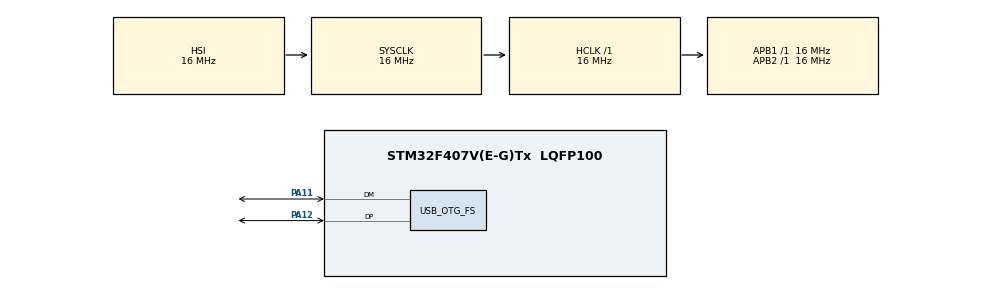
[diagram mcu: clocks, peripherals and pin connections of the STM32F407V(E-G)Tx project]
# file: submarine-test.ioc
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Mcu.Family=STM32F4
Mcu.Name=STM32F407V(E-G)Tx
Mcu.Package=LQFP100
NVIC.OTG_FS_IRQn=true\:0\:0\:false\:false\:true\:false\:true\:true
NVIC.PriorityGroup=NVIC_PRIORITYGROUP_4
PA11.Mode=Device_Only
PA11.Signal=USB_OTG_FS_DM
PA12.Mode=Device_Only
PA12.Signal=USB_OTG_FS_DP
PA13.Mode=Trace_Asynchronous_SW
PA13.Signal=SYS_JTMS-SWDIO
PA14.Mode=Trace_Asynchronous_SW
PA14.Signal=SYS_JTCK-SWCLK
PB3.Mode=Trace_Asynchronous_SW
PB3.Signal=SYS_JTDO-SWO
PH0-OSC_IN.Mode=HSE-External-Oscillator
PH0-OSC_IN.Signal=RCC_OSC_IN
PH1-OSC_OUT.Mode=HSE-External-Oscillator
PH1-OSC_OUT.Signal=RCC_OSC_OUT
ProjectManager.HeapSize=0x200
ProjectManager.StackSize=0x400
ProjectManager.TargetToolchain=STM32CubeIDE
RCC.48MHZClocksFreq_Value=48000000
RCC.AHBFreq_Value=16000000
RCC.APB1Freq_Value=16000000
RCC.APB2Freq_Value=16000000
RCC.CortexFreq_Value=16000000
RCC.HSE_VALUE=25000000
RCC.HSI_VALUE=16000000
RCC.LSE_VALUE=32768
RCC.PLLM=15
RCC.PLLN=144
RCC.PLLQ=5
RCC.SYSCLKFreq_VALUE=16000000
RCC.VCOOutputFreq_Value=240000000
USB_DEVICE.CLASS_NAME_FS=CDC
USB_DEVICE.VirtualMode-CDC_FS=Cdc
USB_DEVICE.VirtualModeFS=Cdc_FS
USB_OTG_FS.VirtualMode=Device_Only
VP_USB_DEVICE_VS_USB_DEVICE_CDC_FS.Mode=CDC_FS
board=custom

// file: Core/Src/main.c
/* USER CODE BEGIN Header */
/**
  ******************************************************************************
  * @file           : main.c
  * @brief          : Main program body
  ******************************************************************************
  * @attention
  *
  * Copyright (c) 2025 STMicroelectronics.
  * All rights reserved.
  *
  * This software is licensed under terms that can be found in the LICENSE file
  * in the root directory of this software component.
  * If no LICENSE file comes with this software, it is provided AS-IS.
  *
  ******************************************************************************
  */
/* USER CODE END Header */
#include "main.h"
#include "usb_device.h"

/* USER CODE BEGIN Includes */
#include <stdio.h>
#include <string.h>
#include "usbd_cdc_if.h"
/* USER CODE END Includes */

void SystemClock_Config(void);
static void MX_GPIO_Init(void);

/* USER CODE BEGIN 0 */

// Redirect printf to USB CDC
int _write(int file, char *ptr, int len)
{
    CDC_Transmit_FS((uint8_t*)ptr, len);
    return len;
}

/* USER CODE END 0 */

int main(void)
{

  /* MCU Configuration--------------------------------------------------------*/

  /* Reset of all peripherals, Initializes the Flash interface and the Systick. */
  HAL_Init();

  /* Configure the system clock */
  SystemClock_Config();

  /* Initialize all configured peripherals */
  MX_GPIO_Init();
  MX_USB_DEVICE_Init();
  /* USER CODE BEGIN 2 */

  // Wait a bit for USB CDC to be ready
  HAL_Delay(1000);

  printf("Hello World!\r\n");
  printf("STM32F407 USB CDC Printf Test\r\n");
  printf("System Clock: %lu Hz\r\n", HAL_RCC_GetSysClockFreq());

  /* USER CODE END 2 */

  /* Infinite loop */
  /* USER CODE BEGIN WHILE */
  uint32_t counter = 0;
  while (1)
  {
    /* USER CODE END WHILE */

    /* USER CODE BEGIN 3 */

    // Turn off both PB0 and PB1 pins completely
    HAL_GPIO_WritePin(GPIOB, GPIO_PIN_0, GPIO_PIN_RESET); // Force PB0 OFF
    HAL_GPIO_WritePin(GPIOB, GPIO_PIN_1, GPIO_PIN_RESET); // PB1 OFF

    // Test only PB1 pin
    printf("Counter: %lu - PB1 turning ON\r\n", counter++);
    HAL_GPIO_WritePin(GPIOB, GPIO_PIN_1, GPIO_PIN_SET);   // Turn on PB1
    HAL_Delay(1000);

    printf("Counter: %lu - PB1 turning OFF\r\n", counter++);
    HAL_GPIO_WritePin(GPIOB, GPIO_PIN_1, GPIO_PIN_RESET); // Turn off PB1
    HAL_Delay(1000);

    printf("Counter: %lu - All pins OFF for 1 second\r\n", counter++);
    HAL_Delay(1000);

  }
  /* USER CODE END 3 */
}

void SystemClock_Config(void)
{
  RCC_OscInitTypeDef RCC_OscInitStruct = {0};
  RCC_ClkInitTypeDef RCC_ClkInitStruct = {0};

  /** Configure the main internal regulator output voltage
  */
  __HAL_RCC_PWR_CLK_ENABLE();
  __HAL_PWR_VOLTAGESCALING_CONFIG(PWR_REGULATOR_VOLTAGE_SCALE1);

  /** Initializes the RCC Oscillators according to the specified parameters
  * in the RCC_OscInitTypeDef structure.
  */
  RCC_OscInitStruct.OscillatorType = RCC_OSCILLATORTYPE_HSI|RCC_OSCILLATORTYPE_HSE;
  RCC_OscInitStruct.HSEState = RCC_HSE_ON;
  RCC_OscInitStruct.HSIState = RCC_HSI_ON;
  RCC_OscInitStruct.HSICalibrationValue = RCC_HSICALIBRATION_DEFAULT;
  RCC_OscInitStruct.PLL.PLLState = RCC_PLL_ON;
  RCC_OscInitStruct.PLL.PLLSource = RCC_PLLSOURCE_HSE;
  RCC_OscInitStruct.PLL.PLLM = 15;
  RCC_OscInitStruct.PLL.PLLN = 144;
  RCC_OscInitStruct.PLL.PLLP = RCC_PLLP_DIV2;
  RCC_OscInitStruct.PLL.PLLQ = 5;
  if (HAL_RCC_OscConfig(&RCC_OscInitStruct) != HAL_OK)
  {
    Error_Handler();
  }

  /** Initializes the CPU, AHB and APB buses clocks
  */
  RCC_ClkInitStruct.ClockType = RCC_CLOCKTYPE_HCLK|RCC_CLOCKTYPE_SYSCLK
                              |RCC_CLOCKTYPE_PCLK1|RCC_CLOCKTYPE_PCLK2;
  RCC_ClkInitStruct.SYSCLKSource = RCC_SYSCLKSOURCE_HSI;
  RCC_ClkInitStruct.AHBCLKDivider = RCC_SYSCLK_DIV1;
  RCC_ClkInitStruct.APB1CLKDivider = RCC_HCLK_DIV1;
  RCC_ClkInitStruct.APB2CLKDivider = RCC_HCLK_DIV1;

  if (HAL_RCC_ClockConfig(&RCC_ClkInitStruct, FLASH_LATENCY_0) != HAL_OK)
  {
    Error_Handler();
  }
}

static void MX_GPIO_Init(void)
{
  GPIO_InitTypeDef GPIO_InitStruct = {0};

  /* GPIO Ports Clock Enable */
  __HAL_RCC_GPIOH_CLK_ENABLE();
  __HAL_RCC_GPIOA_CLK_ENABLE();
  __HAL_RCC_GPIOB_CLK_ENABLE();
  __HAL_RCC_GPIOC_CLK_ENABLE();
  __HAL_RCC_GPIOD_CLK_ENABLE();

  /* USER CODE BEGIN MX_GPIO_Init_2 */

  // Configure LED pins for STM32F407VET6 board
  // User LED 1: PA6, User LED 2: PA7 (both are sink mode - LOW to turn on)
  GPIO_InitStruct.Pin = GPIO_PIN_6|GPIO_PIN_7;
  GPIO_InitStruct.Mode = GPIO_MODE_OUTPUT_PP;
  GPIO_InitStruct.Pull = GPIO_NOPULL;
  GPIO_InitStruct.Speed = GPIO_SPEED_FREQ_LOW;
  HAL_GPIO_Init(GPIOA, &GPIO_InitStruct);

  // Turn off LEDs initially (HIGH = OFF for sink mode)
  HAL_GPIO_WritePin(GPIOA, GPIO_PIN_6|GPIO_PIN_7, GPIO_PIN_SET);

  // Configure PB0 and PB1 to force control both
  GPIO_InitStruct.Pin = GPIO_PIN_0|GPIO_PIN_1;
  GPIO_InitStruct.Mode = GPIO_MODE_OUTPUT_PP;
  GPIO_InitStruct.Pull = GPIO_NOPULL;
  GPIO_InitStruct.Speed = GPIO_SPEED_FREQ_HIGH;
  HAL_GPIO_Init(GPIOB, &GPIO_InitStruct);

  // Force turn off BOTH PB0 and PB1
  HAL_GPIO_WritePin(GPIOB, GPIO_PIN_0, GPIO_PIN_RESET); // Force PB0 OFF
  HAL_GPIO_WritePin(GPIOB, GPIO_PIN_1, GPIO_PIN_RESET); // Force PB1 OFF

  /* USER CODE END MX_GPIO_Init_2 */
}

void Error_Handler(void)
{
  __disable_irq();
  while (1)
  {
  }
}
